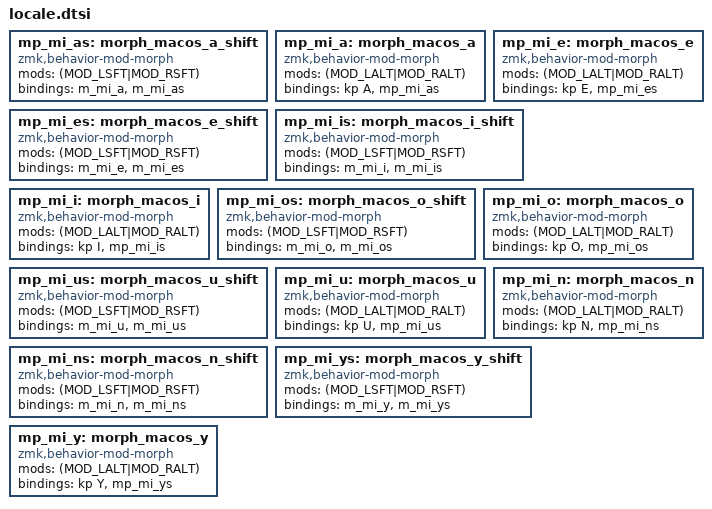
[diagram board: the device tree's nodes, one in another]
// tap:         a
// alt:         á
// alt+shift:   Á
mp_mi_as: morph_macos_a_shift {
    compatible = "zmk,behavior-mod-morph";
    #binding-cells = <0>;
    mods = <(MOD_LSFT|MOD_RSFT)>;
    bindings = <&m_mi_a>, <&m_mi_as>;
};
mp_mi_a: morph_macos_a {
    compatible = "zmk,behavior-mod-morph";
    #binding-cells = <0>;
    mods = <(MOD_LALT|MOD_RALT)>;
    bindings = <&kp A>, <&mp_mi_as>;
};

// tap:         e
// alt:         é
// alt+shift:   É
mp_mi_es: morph_macos_e_shift {
    compatible = "zmk,behavior-mod-morph";
    #binding-cells = <0>;
    mods = <(MOD_LSFT|MOD_RSFT)>;
    bindings = <&m_mi_e>, <&m_mi_es>;
};
mp_mi_e: morph_macos_e {
    compatible = "zmk,behavior-mod-morph";
    #binding-cells = <0>;
    mods = <(MOD_LALT|MOD_RALT)>;
    bindings = <&kp E>, <&mp_mi_es>;
};

// tap:         i
// alt:         í
// alt+shift:   Í
mp_mi_is: morph_macos_i_shift {
    compatible = "zmk,behavior-mod-morph";
    #binding-cells = <0>;
    mods = <(MOD_LSFT|MOD_RSFT)>;
    bindings = <&m_mi_i>, <&m_mi_is>;
};
mp_mi_i: morph_macos_i {
    compatible = "zmk,behavior-mod-morph";
    #binding-cells = <0>;
    mods = <(MOD_LALT|MOD_RALT)>;
    bindings = <&kp I>, <&mp_mi_is>;
};

// tap:         o
// alt:         ó
// alt+shift:   Ó
mp_mi_os: morph_macos_o_shift {
    compatible = "zmk,behavior-mod-morph";
    #binding-cells = <0>;
    mods = <(MOD_LSFT|MOD_RSFT)>;
    bindings = <&m_mi_o>, <&m_mi_os>;
};
mp_mi_o: morph_macos_o {
    compatible = "zmk,behavior-mod-morph";
    #binding-cells = <0>;
    mods = <(MOD_LALT|MOD_RALT)>;
    bindings = <&kp O>, <&mp_mi_os>;
};

// tap:         u
// alt:         ú
// alt+shift:   Ú
mp_mi_us: morph_macos_u_shift {
    compatible = "zmk,behavior-mod-morph";
    #binding-cells = <0>;
    mods = <(MOD_LSFT|MOD_RSFT)>;
    bindings = <&m_mi_u>, <&m_mi_us>;
};
mp_mi_u: morph_macos_u {
    compatible = "zmk,behavior-mod-morph";
    #binding-cells = <0>;
    mods = <(MOD_LALT|MOD_RALT)>;
    bindings = <&kp U>, <&mp_mi_us>;
};

// tap:         n
// alt:         ñ
// alt+shift:   Ñ
mp_mi_ns: morph_macos_n_shift {
    compatible = "zmk,behavior-mod-morph";
    #binding-cells = <0>;
    mods = <(MOD_LSFT|MOD_RSFT)>;
    bindings = <&m_mi_n>, <&m_mi_ns>;
};
mp_mi_n: morph_macos_n {
    compatible = "zmk,behavior-mod-morph";
    #binding-cells = <0>;
    mods = <(MOD_LALT|MOD_RALT)>;
    bindings = <&kp N>, <&mp_mi_ns>;
};

// tap:         y
// alt:         ü
// alt+shift:   Ü
mp_mi_ys: morph_macos_y_shift {
    compatible = "zmk,behavior-mod-morph";
    #binding-cells = <0>;
    mods = <(MOD_LSFT|MOD_RSFT)>;
    bindings = <&m_mi_y>, <&m_mi_ys>;
};
mp_mi_y: morph_macos_y {
    compatible = "zmk,behavior-mod-morph";
    #binding-cells = <0>;
    mods = <(MOD_LALT|MOD_RALT)>;
    bindings = <&kp Y>, <&mp_mi_ys>;
};

